AUTOSAR XML (schema 4-2-1)
standard types defined: boolean, uint16, uint32, uint8
package /VehicleProject
  system System
package /NM
  nm config NmConfig: can-nm-cluster-coupling=coupled-cluster=CAN00_CAN
    can nm cluster CAN00_CAN: communication-cluster=PowerTrain, nm-channel-id=0, nm-msg-cycle-time=2, nm-network-timeout=1, nm-repeat-message-time=0.4, nm-user-data-length=5, nm-wait-bus-sleep-time=0.75
      can nm node Engine: controller=Engine/CT_CAN00, nm-if-ecu=Engine_CAN, nm-node-id=27, tx-nm-pdu=NM_Engine, nm-msg-cycle-offset=0.01, nm-msg-reduced-time=0.05, nm-range-config={lower-can-id=1280, upper-can-id=1407}
      can nm node Gateway: controller=Gateway/CT_CAN00, nm-if-ecu=Gateway_CAN, nm-node-id=26, tx-nm-pdu=NM_Gateway_PowerTrain, nm-msg-cycle-offset=0.01, nm-msg-reduced-time=0.05, nm-range-config={lower-can-id=1280, upper-can-id=1407}
    nm-if-ecus:
      nm ecu Engine_CAN: ecu-instance=Engine, nm-node-id-enabled=true, nm-user-data-enabled=true
      nm ecu Gateway_CAN: ecu-instance=Gateway, nm-node-id-enabled=true, nm-user-data-enabled=true
package /TP
  can tp config CAN00_CAN: communication-cluster=PowerTrain
    can tp channel TPCH: channel-id=0, channel-mode=FULL-DUPLEX-MODE
package /Cluster
  can cluster PowerTrain: baudrate=500000, protocol-name=CAN, can-fd-baudrate=4000000  # demopowertrain | CAN communication matrix for body electronics*******************************************************implemented: turn lights, warning lights, windows
    can physical channel CHNL: comm-connectors=[Engine/CN_CAN00, Gateway/CN_CAN00]
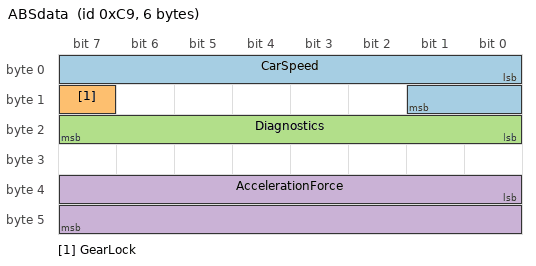
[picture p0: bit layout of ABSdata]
      frame ABSdata: id 0xC9, from Engine, frame-length=6, can-addressing-mode=STANDARD, can-frame-tx-behavior=CAN-20
        pdu ABSdata: length=6, minimum-delay=0.001, transmission-mode-false-timing=cyclic-timing=time-period=0.05, transmission-mode-true-timing=cyclic-timing=time-period=0.05, unused-bit-pattern=0
          signal CarSpeed: start 0, 10 bit, little-endian, init-value=0, base-type=uint16, compu {phys=raw*0.24 for raw 0..1023; unit km/h}, transfer-property=PENDING
          signal GearLock: start 15, 1 bit, little-endian, init-value=0, base-type=boolean, compu {phys=raw for raw 0..1, 0=Gear_Lock_Off, 1=Gear_Lock_On}, transfer-property=PENDING
          signal Diagnostics: start 16, 8 bit, little-endian, init-value=0, base-type=uint8, compu {phys=raw for raw 0..255}, transfer-property=PENDING
          signal AccelerationForce: start 32, 16 bit, little-endian, init-value=0, base-type=uint16, compu {phys=raw-12000 for raw 0..65535; unit N}, transfer-property=PENDING
      frame Diag_Request: id 0x200, frame-length=8, can-addressing-mode=STANDARD
        user defined pdu Diag_Request: length=8
      frame Diag_Response: id 0x400, frame-length=8, can-addressing-mode=STANDARD
        user defined pdu Diag_Response: length=8
      frame DiagRequest_Motor: id 0x601, from Gateway, frame-length=8, can-addressing-mode=STANDARD, can-frame-tx-behavior=CAN-20
        pdu DiagRequest_Motor: length=8, minimum-delay=0.001, unused-bit-pattern=0
          signal DiagRequest: start 0, 64 bit, opaque, system signal DiagRequest_Motor, init-value=8 x 0, base-type=uint8_8_iso_8859_1, compu {phys=raw for raw 0..1.84467440737096e+19}, transfer-property=PENDING
      frame DiagResponse_Motor: id 0x608, from Engine, frame-length=8, can-addressing-mode=STANDARD, can-frame-tx-behavior=CAN-20
        pdu DiagResponse_Motor: length=8, minimum-delay=0.001, unused-bit-pattern=0
          signal DiagResponse: start 0, 64 bit, opaque, system signal DiagResponse_Motor, init-value=8 x 0, base-type=uint8_8_iso_8859_1, compu {phys=raw for raw 0..1.84467440737096e+19}, transfer-property=PENDING
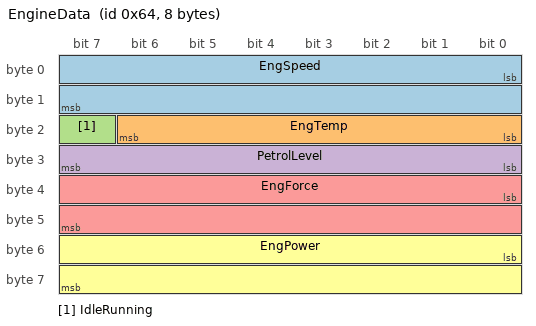
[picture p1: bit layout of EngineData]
      frame EngineData: id 0x64, from Engine, frame-length=8, can-addressing-mode=STANDARD, can-frame-tx-behavior=CAN-20
        pdu EngineData: length=8, minimum-delay=0.001, transmission-mode-condition{data-filter={data-filter-type=MASKED-NEW-DIFFERS-X, mask=1, x=1}, i-signal-in-i-pdu=IdleRunning}, transmission-mode-false-timing=cyclic-timing=time-period=0.1, transmission-mode-true-timing=cyclic-timing=time-period=0.05, unused-bit-pattern=0
          signal EngSpeed: start 0, 16 bit, little-endian, init-value=0, base-type=uint16, compu {phys=raw for raw 0..65535; unit rpm}, transfer-property=PENDING
          signal EngTemp: start 16, 7 bit, little-endian, init-value=0, base-type=uint8, compu {phys=raw for raw 0..127; unit degC}, transfer-property=PENDING
          signal IdleRunning: start 23, 1 bit, little-endian, init-value=0, base-type=boolean, compu {phys=raw for raw 0..1, 0=Running, 1=Idle}, transfer-property=PENDING
          signal PetrolLevel: start 24, 8 bit, little-endian, init-value=0, base-type=uint8, compu {phys=raw*0.2 for raw 0..250; unit l}, transfer-property=PENDING
          signal EngForce: start 32, 16 bit, little-endian, init-value=0, base-type=uint16, compu {phys=raw for raw 0..65535; unit N}, transfer-property=PENDING
          signal EngPower: start 48, 16 bit, little-endian, init-value=0, base-type=uint16, compu {phys=raw*0.01 for raw 0..65535; unit kW}, transfer-property=PENDING
      frame EngineDataIEEE: id 0x66, from Engine, frame-length=12, can-addressing-mode=STANDARD, can-frame-tx-behavior=CAN-FD
        pdu EngineDataIEEE: length=12, minimum-delay=0.001, transmission-mode-false-timing=cyclic-timing=time-period=0.05, transmission-mode-true-timing=cyclic-timing=time-period=0.001, unused-bit-pattern=0
          signal EngSpeedIEEE: start 0, 32 bit, little-endian, init-value=0, base-type=uint32, compu {phys=raw*2e-06 for raw 0..4294967295; unit rpm}, transfer-property=PENDING
          signal EngForceIEEE: start 32, 32 bit, little-endian, init-value=0, base-type=uint32, compu {phys=raw for raw 0..4294967295; unit N}, transfer-property=PENDING
          signal CarSpeedIEEE: start 64, 32 bit, little-endian, system signal CarSpeedIEEE_c814d7fbbb464ecf, data-type-policy=OVERRIDE, base-type=uint32, compu {phys=raw*2e-06 for raw 0..4294967295; unit mph}
      frame EngineStatus: id 0x65, from Engine, frame-length=1, can-addressing-mode=STANDARD, can-frame-tx-behavior=CAN-20
        pdu EngineStatus: length=1, contained-i-pdu-props=trigger=ALWAYS, minimum-delay=0.001, transmission-mode-false-timing=event-controlled-timing={number-of-repetitions=0, repetition-period=0}, transmission-mode-true-timing={cyclic-timing={time-offset=0, time-period=0.01}, event-controlled-timing={number-of-repetitions=0, repetition-period=0}}, unused-bit-pattern=0
          transmission-mode-conditions:
            data-filter=data-filter-type=ALWAYS, i-signal-in-i-pdu=ErrorCode
            data-filter=data-filter-type=ALWAYS, i-signal-in-i-pdu=Status
          signal Status: start 0, 2 bit, little-endian, init-value=0, base-type=uint8, compu {phys=raw for raw 0..3, 0=WakeUp, 1=Running, 2=GoSleep, 3=Error}, transfer-property=PENDING
          signal ErrorCode: start 2, 6 bit, little-endian, init-value=0, base-type=uint8, compu {phys=raw for raw 0..63, 0=NoError}, transfer-property=PENDING
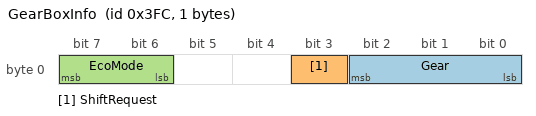
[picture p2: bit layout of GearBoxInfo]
      frame GearBoxInfo: id 0x3FC, from Engine, to Gateway, frame-length=1, can-addressing-mode=STANDARD, can-frame-tx-behavior=CAN-20
        pdu GearBoxInfo: length=1, minimum-delay=0.001, transmission-mode-false-timing=cyclic-timing=time-period=0.05, transmission-mode-true-timing=cyclic-timing=time-period=0.05, unused-bit-pattern=0
          signal Gear: start 0, 3 bit, little-endian, init-value=0, base-type=uint8, compu {phys=raw for raw 0..7, 0=Idle, 1..5=Gear_1..Gear_5}, transfer-property=PENDING, to Gateway
          signal ShiftRequest: start 3, 1 bit, little-endian, init-value=0, base-type=boolean, compu {phys=raw for raw 0..1, 0=Shift_Request_Off, 1=Shift_Request_On}, transfer-property=PENDING
          signal EcoMode: start 6, 2 bit, little-endian, data-type-policy=OVERRIDE, init-value=0, base-type=uint8, compu {phys=raw for raw 0..3, 0=Disabled, 1=Requested, 2=Enabled, 3=Unavailable}, transfer-property=PENDING
      frame Ignition_Info: id 0x67, from Gateway, to Engine, frame-length=2, can-addressing-mode=STANDARD, can-frame-tx-behavior=CAN-20
        pdu Ignition_Info: length=2, minimum-delay=0.001, transmission-mode-false-timing=cyclic-timing=time-period=0.02, transmission-mode-true-timing=cyclic-timing=time-period=0.02, unused-bit-pattern=0
          signal StarterKey: start 0, 1 bit, little-endian, data-type-policy=OVERRIDE, init-value=0, base-type=boolean, compu {phys=raw for raw 0..1, 0=Absent, 1=Present}, transfer-property=PENDING, to Engine
      frame NM_Engine: id 0x51B, from Engine, to Gateway, frame-length=4, can-addressing-mode=STANDARD, can-frame-tx-behavior=CAN-20
        nm pdu NM_Engine: length=4, unused-bit-pattern=0
      frame NM_Gateway_PowerTrain: id 0x51A, from Gateway, to Engine, frame-length=4, can-addressing-mode=STANDARD, can-frame-tx-behavior=CAN-20
        nm pdu NM_Gateway_PowerTrain: length=4, unused-bit-pattern=0
package /ECU
  ecu instance Engine: associated-com-i-pdu-group=[Engine_Rx, Engine_Tx]
    can communication controller CT_CAN00: can-controller-attributes=can-controller-configuration-requirements={max-number-of-time-quanta-per-bit=20, max-sample-point=81.25, min-number-of-time-quanta-per-bit=15, min-sample-point=80}
    can communication connector CN_CAN00: comm-controller=Engine/CT_CAN00
  ecu instance Gateway: associated-com-i-pdu-group=[Gateway_Rx, Gateway_Tx]
    can communication controller CT_CAN00: can-controller-attributes=can-controller-configuration-requirements={max-number-of-time-quanta-per-bit=20, max-sample-point=81.25, min-number-of-time-quanta-per-bit=15, min-sample-point=80}
    can communication connector CN_CAN00: comm-controller=Gateway/CT_CAN00
package /IPDUGroup
  4 x i signal i pdu group:
    Engine_Rx: communication-direction=IN, i-signal-i-pdus=Ignition_Info
    Engine_Tx: communication-direction=OUT, i-signal-i-pdus=[ABSdata, DiagResponse_Motor, EngineData, EngineDataIEEE, EngineStatus, GearBoxInfo]
    Gateway_Rx: communication-direction=IN, i-signal-i-pdus=GearBoxInfo
    Gateway_Tx: communication-direction=OUT, i-signal-i-pdus=[DiagRequest_Motor, Ignition_Info]
package /DataType
  base type uint8_8_iso_8859_1: category=FIXED_LENGTH, base-type-size=64, base-type-encoding=ISO-8859-1
package /VectorAutosarExplorerGeneratedObjects/UNIT
  7 x unit:
    U_degC: display-name=degC
    U_kW: display-name=kW
    U_l: display-name=l
    U_mph: display-name=mph
    U_N: display-name=N
    U_rpm: display-name=rpm
    U_kmh: display-name=km/h
